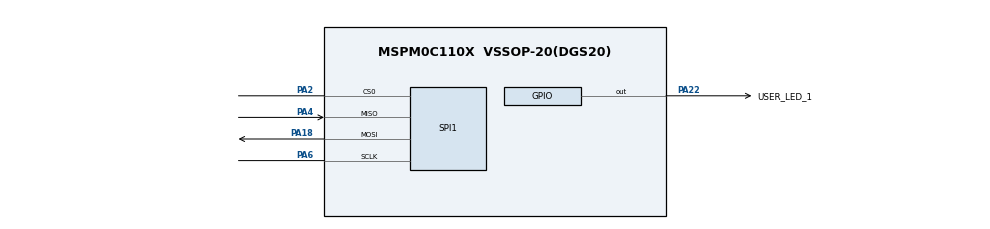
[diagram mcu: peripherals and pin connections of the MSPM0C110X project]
/**
 * @cliArgs --device "MSPM0C110X" --part "Default" --package "VSSOP-20(DGS20)" --product "mspm0_sdk@2.08.00.03"
 * @versions {"tool":"1.25.0+4268"}
 */

/**
 * Import the modules used in this configuration.
 */
const GPIO   = scripting.addModule("/ti/driverlib/GPIO", {}, false);
const GPIO1  = GPIO.addInstance();
const SPI    = scripting.addModule("/ti/driverlib/SPI", {}, false);
const SPI1   = SPI.addInstance();
const SYSCTL = scripting.addModule("/ti/driverlib/SYSCTL");
const UART   = scripting.addModule("/ti/driverlib/UART", {}, false);
const UART1  = UART.addInstance();

/**
 * Write custom configuration values to the imported modules.
 */
GPIO1.$name                         = "GPIO_LEDS";
GPIO1.associatedPins[0].$name       = "USER_LED_1";
GPIO1.associatedPins[0].pin.$assign = "PA22";

const Board = scripting.addModule("/ti/driverlib/Board", {}, false);

SPI1.$name                      = "SPI_0";
SPI1.peripheral.sclkPin.$assign = "PA6";
SPI1.peripheral.mosiPin.$assign = "PA18";
SPI1.peripheral.misoPin.$assign = "PA4";
SPI1.peripheral.cs0Pin.$assign  = "PA2";
SPI1.sclkPinConfig.$name        = "ti_driverlib_gpio_GPIOPinGeneric0";
SPI1.mosiPinConfig.$name        = "ti_driverlib_gpio_GPIOPinGeneric1";
SPI1.misoPinConfig.$name        = "ti_driverlib_gpio_GPIOPinGeneric2";
SPI1.cs0PinConfig.$name         = "ti_driverlib_gpio_GPIOPinGeneric3";

SYSCTL.clockTreeEn = true;

UART1.$name             = "UART_0";
UART1.targetBaudRate    = 115200;
UART1.txPinConfig.$name = "ti_driverlib_gpio_GPIOPinGeneric4";
UART1.rxPinConfig.$name = "ti_driverlib_gpio_GPIOPinGeneric5";

/**
 * Pinmux solution for unlocked pins/peripherals. This ensures that minor changes to the automatic solver in a future
 * version of the tool will not impact the pinmux you originally saw.  These lines can be completely deleted in order to
 * re-solve from scratch.
 */
Board.peripheral.$suggestSolution          = "DEBUGSS";
Board.peripheral.swclkPin.$suggestSolution = "PA20";
Board.peripheral.swdioPin.$suggestSolution = "PA19";
SPI1.peripheral.$suggestSolution           = "SPI0";
UART1.peripheral.$suggestSolution          = "UART0";
UART1.peripheral.rxPin.$suggestSolution    = "PA24";
UART1.peripheral.txPin.$suggestSolution    = "PA17";
